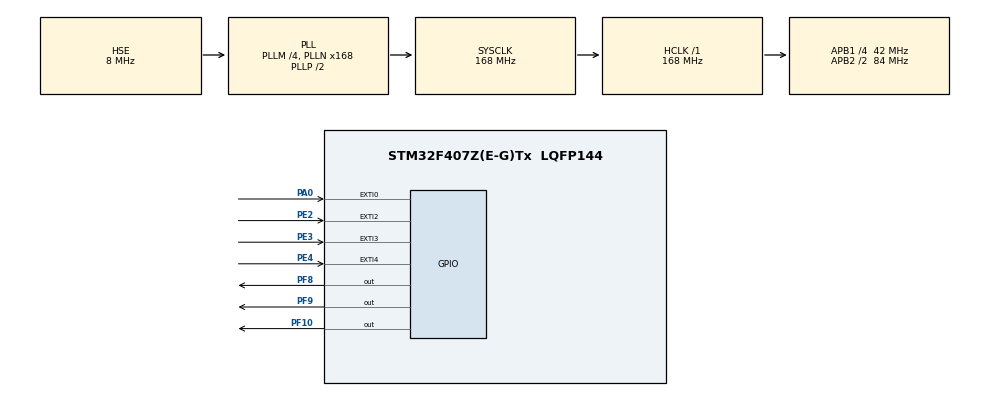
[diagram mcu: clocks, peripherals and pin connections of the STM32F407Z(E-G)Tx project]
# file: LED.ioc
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Mcu.Family=STM32F4
PE3.GPIO_ModeDefaultEXTI=GPIO_MODE_IT_FALLING
RCC.PLLSourceVirtual=RCC_PLLSOURCE_HSE
NVIC.EXTI4_IRQn=true\:1\:0\:true\:false\:true\:true\:true
PH0-OSC_IN.Signal=RCC_OSC_IN
PF10.GPIO_ModeDefaultOutputPP=GPIO_MODE_OUTPUT_PP
RCC.CortexFreq_Value=168000000
PF10.GPIO_Speed=GPIO_SPEED_FREQ_VERY_HIGH
PE4.GPIO_ModeDefaultEXTI=GPIO_MODE_IT_FALLING
NVIC.EXTI3_IRQn=true\:1\:0\:true\:false\:true\:true\:true
PF9.GPIO_Speed=GPIO_SPEED_FREQ_VERY_HIGH
RCC.APB1CLKDivider=RCC_HCLK_DIV4
PF10.GPIO_PuPd=GPIO_PULLUP
PA0-WKUP.GPIO_ModeDefaultEXTI=GPIO_MODE_IT_RISING
RCC.SYSCLKSource=RCC_SYSCLKSOURCE_PLLCLK
ProjectManager.StackSize=0x400
PA0-WKUP.Signal=GPXTI0
PA13.Signal=SYS_JTMS-SWDIO
ProjectManager.TargetToolchain=MDK-ARM V5
PF9.PinState=GPIO_PIN_SET
RCC.HCLKFreq_Value=168000000
RCC.APB2TimFreq_Value=168000000
TIM3.Period=5000-1
RCC.AHBFreq_Value=168000000
PH0-OSC_IN.Mode=HSE-External-Oscillator
PE2.GPIO_PuPd=GPIO_PULLUP
RCC.HSE_VALUE=8000000
board=custom
RCC.VCOOutputFreq_Value=336000000
NVIC.TIM3_IRQn=true\:1\:0\:true\:false\:true\:true\:true
RCC.APB2Freq_Value=84000000
PF8.GPIO_ModeDefaultOutputPP=GPIO_MODE_OUTPUT_PP
PF8.GPIO_PuPd=GPIO_PULLUP
PA14.Mode=Serial_Wire
PF10.Signal=GPIO_Output
TIM3.Prescaler=8400-1
PE3.GPIO_PuPd=GPIO_PULLUP
PH1-OSC_OUT.Signal=RCC_OSC_OUT
PE2.Signal=GPXTI2
PA13.Mode=Serial_Wire
PE4.Signal=GPXTI4
Mcu.Name=STM32F407Z(E-G)Tx
PE4.GPIO_PuPd=GPIO_PULLUP
PH1-OSC_OUT.Mode=HSE-External-Oscillator
RCC.48MHZClocksFreq_Value=84000000
NVIC.EXTI0_IRQn=true\:1\:0\:true\:false\:true\:true\:true
RCC.SYSCLKFreq_VALUE=168000000
Mcu.Package=LQFP144
PA14.Signal=SYS_JTCK-SWCLK
ProjectManager.HeapSize=0x200
PF8.Signal=GPIO_Output
PF9.Signal=GPIO_Output
RCC.HSI_VALUE=16000000
PF9.GPIO_ModeDefaultOutputPP=GPIO_MODE_OUTPUT_PP
NVIC.PriorityGroup=NVIC_PRIORITYGROUP_4
RCC.APB2CLKDivider=RCC_HCLK_DIV2
NVIC.EXTI2_IRQn=true\:1\:0\:true\:false\:true\:true\:true
RCC.PLLM=4
RCC.PLLN=168
PF8.GPIO_Speed=GPIO_SPEED_FREQ_VERY_HIGH
RCC.APB1TimFreq_Value=84000000
PE3.Signal=GPXTI3
PA0-WKUP.GPIO_PuPd=GPIO_PULLDOWN
PE2.GPIO_ModeDefaultEXTI=GPIO_MODE_IT_FALLING
PF9.GPIO_PuPd=GPIO_PULLUP
RCC.APB1Freq_Value=42000000
PF10.PinState=GPIO_PIN_SET
VP_TIM3_VS_ClockSourceINT.Mode=Internal

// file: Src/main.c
/* USER CODE BEGIN Header */
/**
  ******************************************************************************
  * @file           : main.c
  * @brief          : Main program body
  ******************************************************************************
  * @attention
  *
  * <h2><center>&copy; Copyright (c) 2020 STMicroelectronics.
  * All rights reserved.</center></h2>
  *
  * This software component is licensed by ST under BSD 3-Clause license,
  * the "License"; You may not use this file except in compliance with the
  * License. You may obtain a copy of the License at:
  *                        opensource.org/licenses/BSD-3-Clause
  *
  ******************************************************************************
  */
/* USER CODE END Header */

#include "main.h"
#include "tim.h"
#include "gpio.h"

/* USER CODE BEGIN Includes */
#include "key_led_beep.h"

/* USER CODE END Includes */

/* USER CODE BEGIN PV */
uint8_t key;

/* USER CODE END PV */

void SystemClock_Config(void);

int main(void)
{

  /* MCU Configuration--------------------------------------------------------*/

  /* Reset of all peripherals, Initializes the Flash interface and the Systick. */
  HAL_Init();

  /* Configure the system clock */
  SystemClock_Config();

  /* Initialize all configured peripherals */
  MX_GPIO_Init();
  MX_TIM3_Init();
  /* USER CODE BEGIN 2 */
	HAL_TIM_Base_Start_IT(&htim3);
  /* USER CODE END 2 */

  /* Infinite loop */
  /* USER CODE BEGIN WHILE */
  while (1)
  {
//    key=KEY_Scan(0);       //按键扫描
//		switch(key)
//		{
//			case WKUP_PRES:			//控制LED0,LED1互斥点亮
//				LED1;
//				LED0;
//				break;
//			case KEY2_PRES:			//控制LED0翻转
//				LED0;
//				break;
//			case KEY1_PRES:			//控制LED1翻转
//				LED1;
//				break;
//			case KEY0_PRES:			//同时控制LED0,LED1翻转
//				LED0;
//				LED1;
//				break;
//		}

    /* USER CODE END WHILE */

    /* USER CODE BEGIN 3 */
		//HAL_Delay(10);

  }
  /* USER CODE END 3 */
}

void SystemClock_Config(void)
{
  RCC_OscInitTypeDef RCC_OscInitStruct = {0};
  RCC_ClkInitTypeDef RCC_ClkInitStruct = {0};

  /** Configure the main internal regulator output voltage
  */
  __HAL_RCC_PWR_CLK_ENABLE();
  __HAL_PWR_VOLTAGESCALING_CONFIG(PWR_REGULATOR_VOLTAGE_SCALE1);
  /** Initializes the CPU, AHB and APB busses clocks
  */
  RCC_OscInitStruct.OscillatorType = RCC_OSCILLATORTYPE_HSE;
  RCC_OscInitStruct.HSEState = RCC_HSE_ON;
  RCC_OscInitStruct.PLL.PLLState = RCC_PLL_ON;
  RCC_OscInitStruct.PLL.PLLSource = RCC_PLLSOURCE_HSE;
  RCC_OscInitStruct.PLL.PLLM = 4;
  RCC_OscInitStruct.PLL.PLLN = 168;
  RCC_OscInitStruct.PLL.PLLP = RCC_PLLP_DIV2;
  RCC_OscInitStruct.PLL.PLLQ = 4;
  if (HAL_RCC_OscConfig(&RCC_OscInitStruct) != HAL_OK)
  {
    Error_Handler();
  }
  /** Initializes the CPU, AHB and APB busses clocks
  */
  RCC_ClkInitStruct.ClockType = RCC_CLOCKTYPE_HCLK|RCC_CLOCKTYPE_SYSCLK
                              |RCC_CLOCKTYPE_PCLK1|RCC_CLOCKTYPE_PCLK2;
  RCC_ClkInitStruct.SYSCLKSource = RCC_SYSCLKSOURCE_PLLCLK;
  RCC_ClkInitStruct.AHBCLKDivider = RCC_SYSCLK_DIV1;
  RCC_ClkInitStruct.APB1CLKDivider = RCC_HCLK_DIV4;
  RCC_ClkInitStruct.APB2CLKDivider = RCC_HCLK_DIV2;

  if (HAL_RCC_ClockConfig(&RCC_ClkInitStruct, FLASH_LATENCY_5) != HAL_OK)
  {
    Error_Handler();
  }
}

/* USER CODE BEGIN 4 */
//void HAL_GPIO_EXTI_Callback(uint16_t GPIO_Pin)
//{
//    key=GPIO_Pin;       //按键扫描
//		switch(key)
//		{
//			case GPIO_PIN_0:			//控制LED0,LED1互斥点亮
//				LED1;
//				LED0;
//				break;
//			case GPIO_PIN_2:			//控制LED0翻转
//				LED0;
//				break;
//			case GPIO_PIN_3:			//控制LED1翻转
//				LED1;
//				break;
//			case GPIO_PIN_4:			//同时控制LED0,LED1翻转
//				LED0;
//				LED1;
//				break;
//		}
//}

void HAL_TIM_PeriodElapsedCallback(TIM_HandleTypeDef *htim)
{
	if(htim->Instance == TIM3)
	{
	LED0;
	LED1;
	}
}

/* USER CODE END 4 */

void Error_Handler(void)
{
}

/************************ (C) COPYRIGHT STMicroelectronics *****END OF FILE****/
